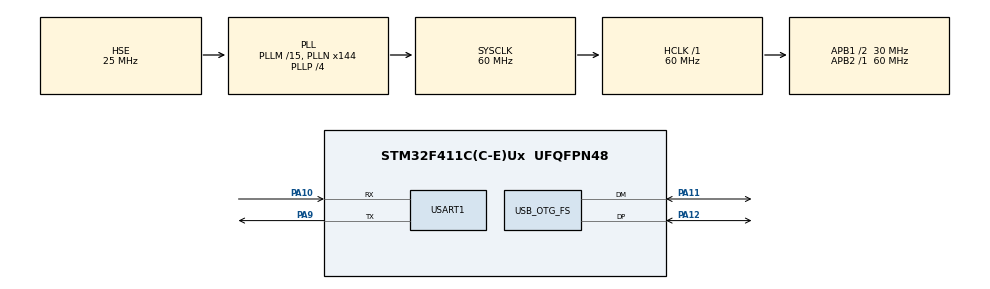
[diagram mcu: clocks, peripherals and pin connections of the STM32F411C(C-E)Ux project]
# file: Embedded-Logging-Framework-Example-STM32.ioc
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Mcu.Family=STM32F4
Mcu.Name=STM32F411C(C-E)Ux
Mcu.Package=UFQFPN48
NVIC.OTG_FS_IRQn=true\:0\:0\:false\:false\:true\:false\:true\:true
NVIC.PriorityGroup=NVIC_PRIORITYGROUP_4
PA10.Mode=Asynchronous
PA10.Signal=USART1_RX
PA11.Mode=Device_Only
PA11.Signal=USB_OTG_FS_DM
PA12.Mode=Device_Only
PA12.Signal=USB_OTG_FS_DP
PA9.Mode=Asynchronous
PA9.Signal=USART1_TX
PC14-OSC32_IN.Mode=LSE-External-Oscillator
PC14-OSC32_IN.Signal=RCC_OSC32_IN
PC15-OSC32_OUT.Mode=LSE-External-Oscillator
PC15-OSC32_OUT.Signal=RCC_OSC32_OUT
PH0\ -\ OSC_IN.Mode=HSE-External-Oscillator
PH0\ -\ OSC_IN.Signal=RCC_OSC_IN
PH1\ -\ OSC_OUT.Mode=HSE-External-Oscillator
PH1\ -\ OSC_OUT.Signal=RCC_OSC_OUT
ProjectManager.HeapSize=0x200
ProjectManager.StackSize=0x400
ProjectManager.TargetToolchain=STM32CubeIDE
RCC.48MHZClocksFreq_Value=48000000
RCC.AHBFreq_Value=60000000
RCC.APB1CLKDivider=RCC_HCLK_DIV2
RCC.APB1Freq_Value=30000000
RCC.APB1TimFreq_Value=60000000
RCC.APB2Freq_Value=60000000
RCC.APB2TimFreq_Value=60000000
RCC.CortexFreq_Value=60000000
RCC.HCLKFreq_Value=60000000
RCC.HSE_VALUE=25000000
RCC.HSI_VALUE=16000000
RCC.PLLM=15
RCC.PLLN=144
RCC.PLLP=RCC_PLLP_DIV4
RCC.PLLQ=5
RCC.SYSCLKFreq_VALUE=60000000
RCC.SYSCLKSource=RCC_SYSCLKSOURCE_PLLCLK
RCC.VCOOutputFreq_Value=240000000
USART1.VirtualMode=VM_ASYNC
USB_DEVICE.CLASS_NAME_FS=CDC
USB_DEVICE.VirtualMode=Cdc
USB_DEVICE.VirtualModeFS=Cdc_FS
USB_OTG_FS.VirtualMode=Device_Only
VP_USB_DEVICE_VS_USB_DEVICE_CDC_FS.Mode=CDC_FS
board=custom

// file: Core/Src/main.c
/* USER CODE BEGIN Header */
/**
  ******************************************************************************
  * @file           : main.c
  * @brief          : Main program body
  ******************************************************************************
  * @attention
  *
  * Copyright (c) 2026 STMicroelectronics.
  * All rights reserved.
  *
  * This software is licensed under terms that can be found in the LICENSE file
  * in the root directory of this software component.
  * If no LICENSE file comes with this software, it is provided AS-IS.
  *
  ******************************************************************************
  */
/* USER CODE END Header */
#include "main.h"
#include "usb_device.h"

/* USER CODE BEGIN Includes */
#include "osal.h"
#include "debug.h"
/* USER CODE END Includes */

UART_HandleTypeDef huart1;

void SystemClock_Config(void);
static void MX_GPIO_Init(void);
static void MX_USART1_UART_Init(void);

/* USER CODE BEGIN 0 */
static debug_transport_t debug_trans;
static osal_t osal;
/* USER CODE END 0 */

int main(void)
{

  /* MCU Configuration--------------------------------------------------------*/

  /* Reset of all peripherals, Initializes the Flash interface and the Systick. */
  HAL_Init();

  /* Configure the system clock */
  SystemClock_Config();

  /* Initialize all configured peripherals */
  MX_GPIO_Init();
  MX_USART1_UART_Init();
  MX_USB_DEVICE_Init();
  /* USER CODE BEGIN 2 */

  osal_init(&osal, get_osal_ops());

  debug_transport_init(&debug_trans);

  debug_init(&debug_trans, &osal);

  /* USER CODE END 2 */

  /* Infinite loop */
  while (1)
  {
	  LOG_ERROR("Fatal error: %d\r\n", -1);
	  LOG_WARN("Battery low\r\n");
	  LOG_INFO("System ready\r\n");
	  LOG_DEBUG("Debug info: %d\r\n", 42);
	  HAL_Delay(1000);
  }
}

void SystemClock_Config(void)
{
  RCC_OscInitTypeDef RCC_OscInitStruct = {0};
  RCC_ClkInitTypeDef RCC_ClkInitStruct = {0};

  /** Configure the main internal regulator output voltage
  */
  __HAL_RCC_PWR_CLK_ENABLE();
  __HAL_PWR_VOLTAGESCALING_CONFIG(PWR_REGULATOR_VOLTAGE_SCALE1);

  /** Initializes the RCC Oscillators according to the specified parameters
  * in the RCC_OscInitTypeDef structure.
  */
  RCC_OscInitStruct.OscillatorType = RCC_OSCILLATORTYPE_HSE;
  RCC_OscInitStruct.HSEState = RCC_HSE_ON;
  RCC_OscInitStruct.PLL.PLLState = RCC_PLL_ON;
  RCC_OscInitStruct.PLL.PLLSource = RCC_PLLSOURCE_HSE;
  RCC_OscInitStruct.PLL.PLLM = 15;
  RCC_OscInitStruct.PLL.PLLN = 144;
  RCC_OscInitStruct.PLL.PLLP = RCC_PLLP_DIV4;
  RCC_OscInitStruct.PLL.PLLQ = 5;
  if (HAL_RCC_OscConfig(&RCC_OscInitStruct) != HAL_OK)
  {
    Error_Handler();
  }

  /** Initializes the CPU, AHB and APB buses clocks
  */
  RCC_ClkInitStruct.ClockType = RCC_CLOCKTYPE_HCLK|RCC_CLOCKTYPE_SYSCLK
                              |RCC_CLOCKTYPE_PCLK1|RCC_CLOCKTYPE_PCLK2;
  RCC_ClkInitStruct.SYSCLKSource = RCC_SYSCLKSOURCE_PLLCLK;
  RCC_ClkInitStruct.AHBCLKDivider = RCC_SYSCLK_DIV1;
  RCC_ClkInitStruct.APB1CLKDivider = RCC_HCLK_DIV2;
  RCC_ClkInitStruct.APB2CLKDivider = RCC_HCLK_DIV1;

  if (HAL_RCC_ClockConfig(&RCC_ClkInitStruct, FLASH_LATENCY_1) != HAL_OK)
  {
    Error_Handler();
  }
}

static void MX_USART1_UART_Init(void)
{

  huart1.Instance = USART1;
  huart1.Init.BaudRate = 115200;
  huart1.Init.WordLength = UART_WORDLENGTH_8B;
  huart1.Init.StopBits = UART_STOPBITS_1;
  huart1.Init.Parity = UART_PARITY_NONE;
  huart1.Init.Mode = UART_MODE_TX_RX;
  huart1.Init.HwFlowCtl = UART_HWCONTROL_NONE;
  huart1.Init.OverSampling = UART_OVERSAMPLING_16;
  if (HAL_UART_Init(&huart1) != HAL_OK)
  {
    Error_Handler();
  }

}

static void MX_GPIO_Init(void)
{

  /* GPIO Ports Clock Enable */
  __HAL_RCC_GPIOC_CLK_ENABLE();
  __HAL_RCC_GPIOH_CLK_ENABLE();
  __HAL_RCC_GPIOA_CLK_ENABLE();

}

void Error_Handler(void)
{
  __disable_irq();
  while (1)
  {
  }
}
